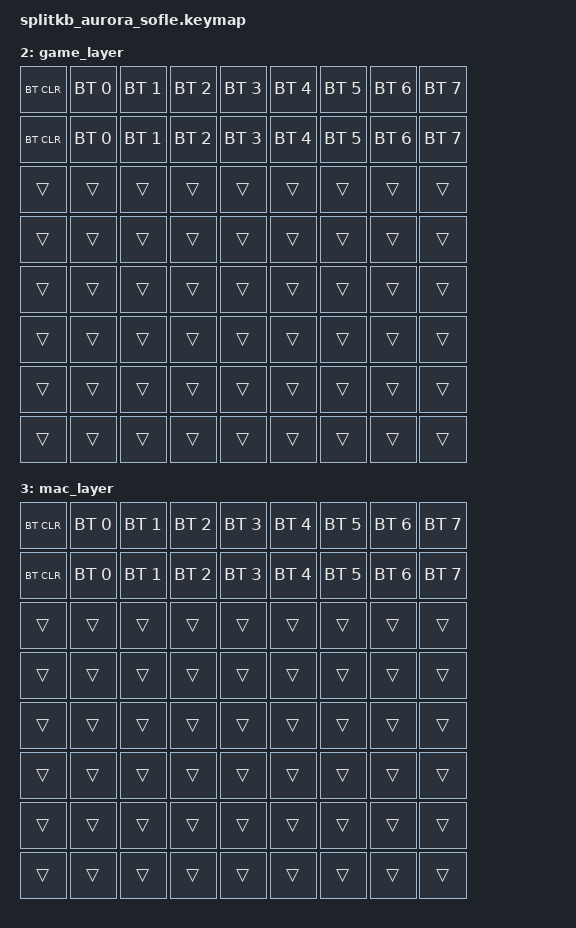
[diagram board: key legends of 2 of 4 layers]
/*
 * Copyright (c) 2023 The ZMK Contributors
 *
 * SPDX-License-Identifier: MIT
 */

#include <behaviors.dtsi>
#include <dt-bindings/zmk/keys.h>
#include <dt-bindings/zmk/bt.h>
#include <dt-bindings/zmk/ext_power.h>

/* Uncomment this block if using RGB
&led_strip {
    chain-length = <6>;
    // chain-length = <35>; // Uncomment if using both per-key and underglow LEDs
    // chain-length = <29>; // Uncomment if using only per-key LEDs.
};
 */
#define DEFAULT 0
#define INTERFACE 1
#define GAME   2
#define MAC 3
/ {
    keymap {
        compatible = "zmk,keymap";

        default_layer {
            bindings = <
            &kp ESC   &kp ESC   &kp F1   &kp F2   &kp F3   &kp F4   &kp F5   &kp F6   &kp F7   &kp F8   &kp F9   &kp F10  &kp F11  &kp F12  &kp F10  &kp F10  &kp F10  &kp PG_UP  &kp PG_DN  &kp DEL
            &kp HOME  &kp GRAVE &kp N1   &kp N2   &kp N3   &kp N4   &kp N5   &kp N6   &kp N7   &kp N8   &kp N9   &kp N0   &kp MINUS &kp EQUAL &kp BSPC  &kp KP_NUMLOCK &kp KP_SLASH &kp KP_ASTERISK &kp KP_MINUS &trans
            &kp END   &kp TAB   &kp Q    &kp W    &kp E    &kp R    &kp T    &trans   &kp Y    &kp U    &kp I    &kp O    &kp P &kp LBKT  &kp RBKT  &kp BSLH  &kp N7  &kp N8  &kp N9  &kp KP_PLUS
            &kp PG_UP &kp CAPS  &kp A    &kp S    &kp D    &kp F    &kp G    &trans   &kp H    &kp J    &kp K    &kp L    &kp SEMI &kp APOS  &kp ENTER &kp N4  &kp N5  &kp N6  &kp KP_PLUS &trans
            &kp PG_DN &kp LSHFT &kp Z    &kp X    &kp C    &kp V    &kp B    &trans   &kp B    &kp N    &kp M    &kp COMMA &kp DOT  &kp SLASH &kp RSHFT &kp UP    &kp N1  &kp N2  &kp N3  &kp KP_ENTER
            &kp LEFT  &kp LCTRL &kp LGUI &mo INTERFACE    &kp LALT &kp P &kp SPACE &kp SPACE &kp SPACE &kp SPACE &kp SPACE &kp RALT &mo INTERFACE  &kp RCTRL &kp LEFT &kp DOWN &kp RIGHT &kp N0 &kp KP_DOT &kp KP_ENTER
            >;
        };

        interface_layer {
            bindings = <
            &bt BT_CLR &bt BT_SEL 0 &bt BT_SEL 1 &bt BT_SEL 2 &bt BT_SEL 3 &bt BT_SEL 4 &bt BT_SEL 5 &bt BT_SEL 6 &bt BT_SEL 7
            &bt BT_CLR &bt BT_SEL 0 &bt BT_SEL 1 &bt BT_SEL 2 &bt BT_SEL 3 &bt BT_SEL 4 &bt BT_SEL 5 &bt BT_SEL 6 &bt BT_SEL 7
            &out OUT_USB &out OUT_BLE &trans &trans &trans &trans &trans &trans &trans
            &out OUT_USB &out OUT_BLE &trans &trans &trans &trans &trans &trans &trans
            &ext_power EP_ON &ext_power EP_OFF &trans &trans &trans &trans &trans &trans &trans
            &ext_power EP_ON &ext_power EP_OFF &trans &trans &trans &trans &trans &trans &trans
            &sys_reset &bootloader &trans &trans &trans &trans &trans &trans &trans
            &sys_reset &bootloader &trans &trans &trans &trans &trans &trans &trans
            &rgb_ug RGB_TOG &rgb_ug RGB_HUI &rgb_ug RGB_SAI &rgb_ug RGB_BRI &rgb_ug RGB_SPI &rgb_ug RGB_EFF &trans &trans &trans
            &rgb_ug RGB_TOG &rgb_ug RGB_HUI &rgb_ug RGB_SAI &rgb_ug RGB_BRI &rgb_ug RGB_SPI &rgb_ug RGB_EFF &trans &trans &trans
            &trans &rgb_ug RGB_HUD &rgb_ug RGB_SAD &rgb_ug RGB_BRD &rgb_ug RGB_SPD &rgb_ug RGB_EFR &trans &trans &trans
            &trans &rgb_ug RGB_HUD &rgb_ug RGB_SAD &rgb_ug RGB_BRD &rgb_ug RGB_SPD &rgb_ug RGB_EFR &trans &trans &trans
            >;
        };

        game_layer {
            bindings = <
            &bt BT_CLR &bt BT_SEL 0 &bt BT_SEL 1 &bt BT_SEL 2 &bt BT_SEL 3 &bt BT_SEL 4 &bt BT_SEL 5 &bt BT_SEL 6 &bt BT_SEL 7
            &bt BT_CLR &bt BT_SEL 0 &bt BT_SEL 1 &bt BT_SEL 2 &bt BT_SEL 3 &bt BT_SEL 4 &bt BT_SEL 5 &bt BT_SEL 6 &bt BT_SEL 7
            &trans &trans &trans &trans &trans &trans &trans &trans &trans
            &trans &trans &trans &trans &trans &trans &trans &trans &trans
            &trans &trans &trans &trans &trans &trans &trans &trans &trans
            &trans &trans &trans &trans &trans &trans &trans &trans &trans
            &trans &trans &trans &trans &trans &trans &trans &trans &trans
            &trans &trans &trans &trans &trans &trans &trans &trans &trans
            >;
        };

        mac_layer {
            bindings = <
            &bt BT_CLR &bt BT_SEL 0 &bt BT_SEL 1 &bt BT_SEL 2 &bt BT_SEL 3 &bt BT_SEL 4 &bt BT_SEL 5 &bt BT_SEL 6 &bt BT_SEL 7
            &bt BT_CLR &bt BT_SEL 0 &bt BT_SEL 1 &bt BT_SEL 2 &bt BT_SEL 3 &bt BT_SEL 4 &bt BT_SEL 5 &bt BT_SEL 6 &bt BT_SEL 7
            &trans &trans &trans &trans &trans &trans &trans &trans &trans
            &trans &trans &trans &trans &trans &trans &trans &trans &trans
            &trans &trans &trans &trans &trans &trans &trans &trans &trans
            &trans &trans &trans &trans &trans &trans &trans &trans &trans
            &trans &trans &trans &trans &trans &trans &trans &trans &trans
            &trans &trans &trans &trans &trans &trans &trans &trans &trans
            >;
        };
    };
};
